# PIC16F1513 register map
Vendor: Microchip
Registers are 8-bit, read-write, reset 0x0 unless marked. A register's access mark holds for its fields unless they carry their own. Addresses are absolute, and some are shared; only a register's first bit layout is shown; [hi:lo] are bit positions; {n}, {i} and the like mark numbered series.

## SFR
0x00 INDF0 reset not defined — (power-on value xxxxxxxx)
0x01 INDF1 reset not defined — (power-on value xxxxxxxx)
0x02 PCL
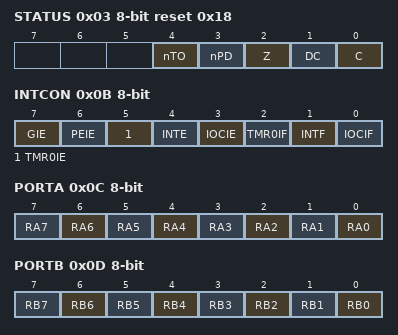
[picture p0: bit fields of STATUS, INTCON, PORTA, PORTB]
0x03 STATUS reset 0x18
  [4] nTO ro, [3] nPD ro, [2] Z, [1] DC, [0] C
0x04 FSR0L
0x05 FSR0H
0x06 FSR1L
0x07 FSR1H
0x08 BSR
  [4:0] BSR
0x09 WREG
  [7:0] WREG0
0x0A PCLATH
  [6:0] PCLATH
0x0B INTCON
  [7] GIE, [6] PEIE, [5] TMR0IE, [4] INTE, [3] IOCIE, [2] TMR0IF, [1] INTF, [0] IOCIF ro
0x0C PORTA reset not defined — (power-on value xxxxxxxx)
  [n] RA{n} (n=0..7)
0x0D PORTB reset not defined — (power-on value xxxxxxxx)
  [n] RB{n} (n=0..7)
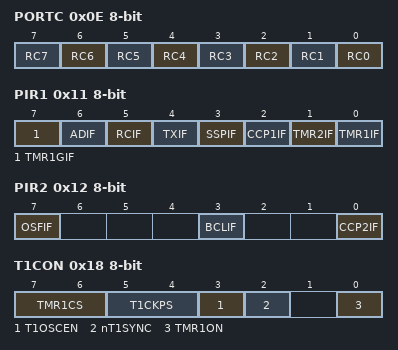
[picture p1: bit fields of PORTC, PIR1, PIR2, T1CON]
0x0E PORTC reset not defined — (power-on value xxxxxxxx)
  [n] RC{n} (n=0..7)
0x10 PORTE ro reset not defined — (power-on value ----x---)
  [3] RE3
0x11 PIR1
  [7] TMR1GIF — Timer1 Gate Interrupt Flag bit
  [6] ADIF — A/D Converter Interrupt Flag bit
  [5] RCIF ro — EUSART Receive Interrupt Flag bit
  [4] TXIF ro — EUSART Transmit Interrupt Flag bit
  [3] SSPIF — Master Synchronous Serial Port (MSSP) Interrupt Flag bit
  [2] CCP1IF — CCP1 Interrupt Flag bit
  [1] TMR2IF — TMR2 to PR2 Match Interrupt Flag bit
  [0] TMR1IF — TMR1 Overflow Interrupt Flag bit
0x12 PIR2
  [7] OSFIF, [3] BCLIF, [0] CCP2IF
0x15 TMR0 reset not defined — (power-on value xxxxxxxx)
0x16 TMR1L reset not defined — (power-on value xxxxxxxx)
0x17 TMR1H reset not defined — (power-on value xxxxxxxx)
0x18 T1CON
  [7:6] TMR1CS, [5:4] T1CKPS, [3] T1OSCEN, [2] nT1SYNC, [0] TMR1ON
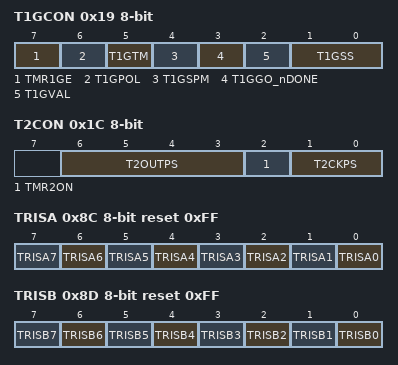
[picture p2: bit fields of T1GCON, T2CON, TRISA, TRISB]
0x19 T1GCON reset not defined — (power-on value 00000x00)
  [7] TMR1GE, [6] T1GPOL, [5] T1GTM, [4] T1GSPM, [3] T1GGO_nDONE, [2] T1GVAL ro, [1:0] T1GSS
0x1A TMR2
0x1B PR2 reset 0xFF
0x1C T2CON
  [6:3] T2OUTPS, [2] TMR2ON, [1:0] T2CKPS
0x8C TRISA reset 0xFF — PORTA Data Direction Control Register
  [n] TRISA{n} (n=0..7)
0x8D TRISB reset 0xFF — PORTB Data Direction Control Register
  [n] TRISB{n} (n=0..7)
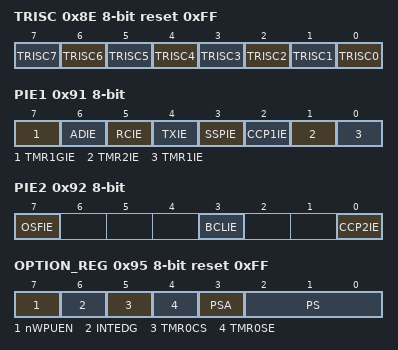
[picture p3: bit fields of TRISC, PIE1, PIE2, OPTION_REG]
0x8E TRISC reset 0xFF — PORTC Data Direction Control Register
  [n] TRISC{n} (n=0..7)
0x90 TRISE access not given reset 0x8
0x91 PIE1 — Peripheral Interrupt Enable Register 1
  [7] TMR1GIE — Timer1 Gate Interrupt Enable bit
  [6] ADIE — A/D Converter Interrupt Enable bit
  [5] RCIE — EUSART Receive Interrupt Enable bit
  [4] TXIE — EUSART Transmit Interrupt Enable bit
  [3] SSPIE — Master Synchronous Serial Port (MSSP) Interrupt Enable bit
  [2] CCP1IE — CCP1 Interrupt Enable bit
  [1] TMR2IE — TMR2 to PR2 Match Interrupt Enable bit
  [0] TMR1IE — TMR1 Overflow Interrupt Enable bit
0x92 PIE2 — Peripheral Interrupt Enable Register 2
  [7] OSFIE — CCP2 Interrupt Enable bit
  [3] BCLIE — MSSP Bus Collision Interrupt Interrupt Enable bit
  [0] CCP2IE — CCP2 Interrupt Enable bit
0x95 OPTION_REG reset 0xFF — Option Register
  [7] nWPUEN — Weak Pull-up Enable bit
  [6] INTEDG — Interrupt Edge Select bit
  [5] TMR0CS — TMR0 Clock Source Select bit
  [4] TMR0SE — TMR0 Source Edge Select bit
  [3] PSA — Prescaler Active bit
  [2:0] PS
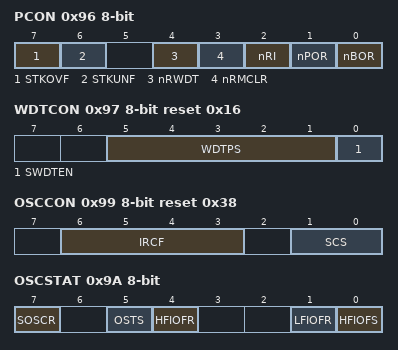
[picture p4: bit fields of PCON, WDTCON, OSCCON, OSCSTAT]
0x96 PCON reset not defined — Power Control Register (power-on value 00-111qq)
  [7] STKOVF — Stack Overflow Flag bit
  [6] STKUNF — Stack Underflow Flag bit
  [4] nRWDT
  [3] nRMCLR — MCLR Reset Flag bit
  [2] nRI — RESET Instruction Flag bit
  [1] nPOR — Power-on Reset Status bit
  [0] nBOR — Brown-out Reset Status bit
0x97 WDTCON reset 0x16 — Watchdog Timer Control Register
  [5:1] WDTPS
  [0] SWDTEN — Software Enable/Disable for Watch Dog Timer bit
0x99 OSCCON reset 0x38 — Oscillator Control Register
  [6:3] IRCF, [1:0] SCS
0x9A OSCSTAT ro reset not defined — Oscillator Status Register (power-on value 0-q0--00)
  [7] SOSCR — Timer1 Oscillator Ready bit
  [5] OSTS — Oscillator Start-up Time-out Status bit
  [4] HFIOFR
  [1] LFIOFR — Low Freqency Internal Oscillator Ready bit
  [0] HFIOFS — Low Freqency Internal Oscillator Ready bit
0x9B ADRES0L reset not defined — A/D Result Register LSB (power-on value xxxxxxxx)
0x9C ADRES0H reset not defined — A/D Result Register MSB (power-on value xxxxxxxx)
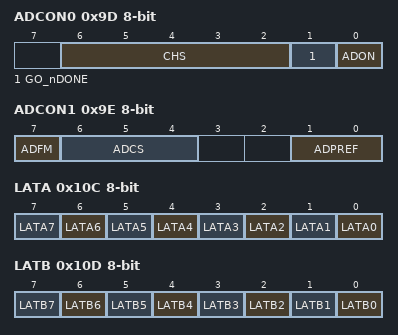
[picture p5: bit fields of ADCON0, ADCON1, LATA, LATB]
0x9D ADCON0 — Analog-to-Digital Control Register 0
  [6:2] CHS
  [1] GO_nDONE — A/D Conversion Status bit
  [0] ADON — A/D Module Enable bit
0x9E ADCON1 — Analog-to-Digital Control Register 1
  [7] ADFM — A/D Result Format Select bit
  [6:4] ADCS
  [1:0] ADPREF
0x10C LATA reset not defined — (power-on value xxxxxxxx)
  [n] LATA{n} (n=0..7)
0x10D LATB reset not defined — (power-on value xxxxxxxx)
  [n] LATB{n} (n=0..7)
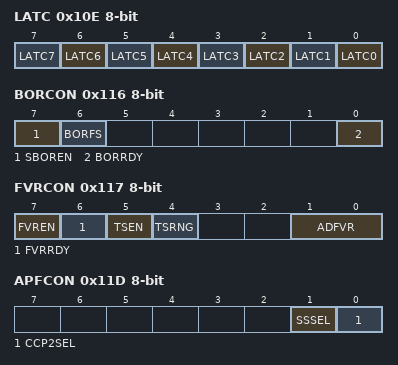
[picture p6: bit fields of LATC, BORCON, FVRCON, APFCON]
0x10E LATC reset not defined — (power-on value xxxxxxxx)
  [n] LATC{n} (n=0..7)
0x116 BORCON reset not defined — Brown-out Reset Control Register (power-on value 10-----q)
  [7] SBOREN — Software Brown Out Reset Enable bit
  [6] BORFS
  [0] BORRDY ro — Brown-out Reset Circuit Ready Status bit
0x117 FVRCON reset not defined — Voltage Reference Control Register 0 (power-on value 0q00--00)
  [7] FVREN — Fixed Voltage Reference Enable
  [6] FVRRDY ro — Fixed Voltage Reference Ready Flag
  [5] TSEN — Temperature Sensor Enable
  [4] TSRNG — Temperature Sensor Range Select
  [1:0] ADFVR — A/D Converter Fixed Voltage Reference Selection
0x11D APFCON — Alternate Pin Function Control Register
  [1] SSSEL — SS Input Pin Selection
  [0] CCP2SEL — CCP2 Input/Output Pin Selection
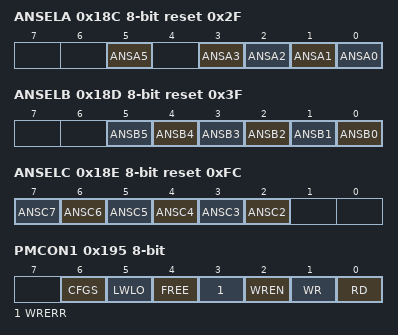
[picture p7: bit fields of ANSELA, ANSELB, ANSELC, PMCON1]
0x18C ANSELA reset 0x2F
  [5] ANSA5, [n] ANSA{n} (n=0..3)
0x18D ANSELB reset 0x3F
  [n] ANSB{n} (n=0..5)
0x18E ANSELC reset 0xFC
  [n] ANSC{n} (n=2..7)
0x191 PMADRL
0x192 PMADRH reset 0x80
  [6:0] PMADRH
0x193 PMDATL reset not defined — (power-on value xxxxxxxx)
0x194 PMDATH reset not defined — (power-on value --xxxxxx)
  [5:0] PMDATH
0x195 PMCON1 reset not defined — (power-on value 1000x000)
  [6] CFGS — FLASH Program / Data EEPROM or Configuration Select bit
  [5] LWLO — Load Write Latches Only bit
  [4] FREE — Program FLASH Erase Enable bit
  [3] WRERR — Sequence Error Flag bit
  [2] WREN — Program/Erase Enable bit
  [1] WR — Write Control bit (can only be set)
  [0] RD — Read Control bit (can only be set)
0x196 PMCON2 wo reset not defined
0x197 VREGCON
  [1] VREGPM
0x199 RCREG ro
0x19A TXREG
0x19B SP1BRGL
  [7:0] SPBRGL
0x19C SP1BRGH
  [7:0] SPBRGH
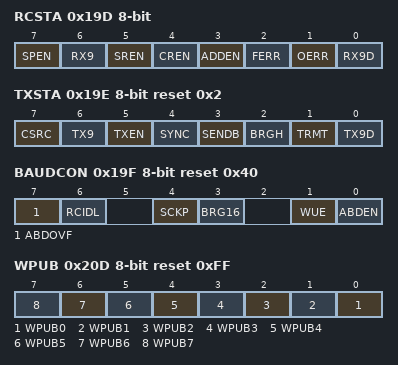
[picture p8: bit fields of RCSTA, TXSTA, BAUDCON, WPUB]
0x19D RCSTA reset not defined — Receive Status and Control Register (power-on value 0000000x)
  [7] SPEN — Serial Port Enable bit
  [6] RX9 — 9-bit Receive Enable bit
  [5] SREN — Single Receive Enable bit
  [4] CREN — Continuous Receive Enable bit
  [3] ADDEN — Address Detect Enable bit
  [2] FERR ro — Framing Error bit
  [1] OERR ro — Overrun Error bit
  [0] RX9D ro — 9th bit of received data (can be parity bit)
0x19E TXSTA reset 0x2 — Transmit Status and Control Register
  [7] CSRC — Clock Source Select bit
  [6] TX9 — 9-bit Transmit Enable bit
  [5] TXEN — Transmit Enable bit
  [4] SYNC — USART Mode Select bit
  [3] SENDB — Send BREAK character bit
  [2] BRGH — High Baud Rate Select bit
  [1] TRMT ro — Transmit Operation Idle Status bit
  [0] TX9D — 9th bit of transmit data; can be used as parity bit
0x19F BAUDCON reset 0x40 — Baud Rate Control Register
  [7] ABDOVF — BRG Rollover Status bit
  [6] RCIDL ro — Receive Operation Idle Status bit
  [4] SCKP — Clock/Transmit Polarity Select bit
  [3] BRG16 — 16-bit Baud Rate Register enable bit
  [1] WUE — Wake-Up Enable bit
  [0] ABDEN — Auto-Baud Detect Enable bit
0x20D WPUB reset 0xFF
  [n] WPUB{n} (n=0..7)
0x210 WPUE reset 0x8
  [3] WPUE3
0x211 SSPBUF reset not defined — (power-on value xxxxxxxx)
0x212 SSPADD
0x213 SSPMSK reset 0xFF
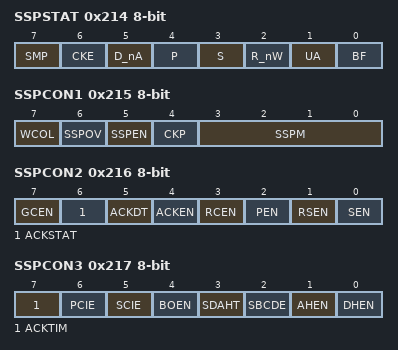
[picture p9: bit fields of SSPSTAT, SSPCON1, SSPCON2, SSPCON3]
0x214 SSPSTAT
  [7] SMP, [6] CKE, [5] D_nA, [4] P, [3] S, [2] R_nW, [1] UA, [0] BF
0x215 SSPCON1
  [7] WCOL, [6] SSPOV, [5] SSPEN, [4] CKP, [3:0] SSPM
0x216 SSPCON2
  [7] GCEN, [6] ACKSTAT, [5] ACKDT, [4] ACKEN, [3] RCEN, [2] PEN, [1] RSEN, [0] SEN
0x217 SSPCON3
  [7] ACKTIM, [6] PCIE, [5] SCIE, [4] BOEN, [3] SDAHT, [2] SBCDE, [1] AHEN, [0] DHEN
0x291 CCPR1L reset not defined — (power-on value xxxxxxxx)
0x292 CCPR1H reset not defined — (power-on value xxxxxxxx)
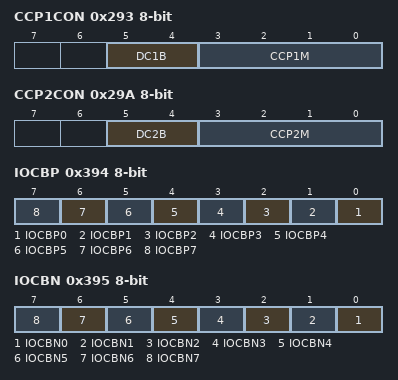
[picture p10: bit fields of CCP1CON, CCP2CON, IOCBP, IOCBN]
0x293 CCP1CON
  [5:4] DC1B, [3:0] CCP1M
0x298 CCPR2L reset not defined — (power-on value xxxxxxxx)
0x299 CCPR2H reset not defined — (power-on value xxxxxxxx)
0x29A CCP2CON
  [5:4] DC2B, [3:0] CCP2M
0x394 IOCBP — Interrupt-On-Change Positive Edge Register
  [n] IOCBP{n} (n=0..7)
0x395 IOCBN — Interrupt-On-Change Negative Edge Register
  [n] IOCBN{n} (n=0..7)
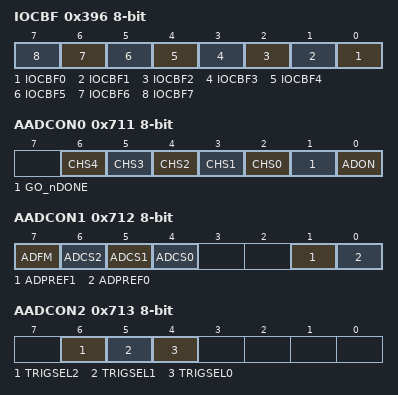
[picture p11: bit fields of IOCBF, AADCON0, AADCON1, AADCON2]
0x396 IOCBF — Interrupt-On-Change Flag Register
  [n] IOCBF{n} (n=0..7)
0x711 AADCON0
  [n+2] CHS{n} (n=0..4), [1] GO_nDONE, [0] ADON
0x712 AADCON1
  [7] ADFM, [6] ADCS2, [5] ADCS1, [4] ADCS0, [1] ADPREF1, [0] ADPREF0
0x713 AADCON2
  [6] TRIGSEL2, [5] TRIGSEL1, [4] TRIGSEL0
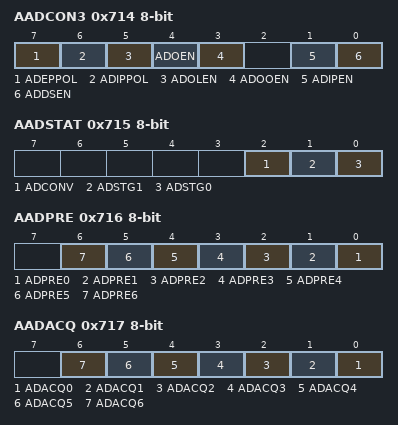
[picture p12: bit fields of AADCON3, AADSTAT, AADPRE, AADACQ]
0x714 AADCON3
  [7] ADEPPOL, [6] ADIPPOL, [5] ADOLEN, [4] ADOEN, [3] ADOOEN, [1] ADIPEN, [0] ADDSEN
0x715 AADSTAT
  [2] ADCONV, [1] ADSTG1, [0] ADSTG0
0x716 AADPRE
  [n] ADPRE{n} (n=0..6)
0x717 AADACQ
  [n] ADACQ{n} (n=0..6)
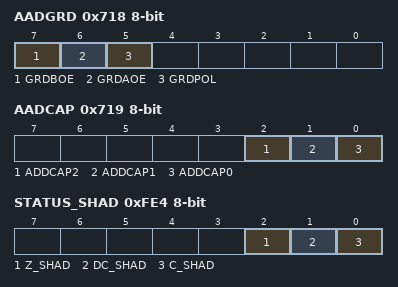
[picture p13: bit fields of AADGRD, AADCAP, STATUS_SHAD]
0x718 AADGRD
  [7] GRDBOE, [6] GRDAOE, [5] GRDPOL
0x719 AADCAP
  [2] ADDCAP2, [1] ADDCAP1, [0] ADDCAP0
0x71A AADRES0L reset not defined — (power-on value xxxxxxxx)
  [7:0] ADRES0L
0x71B AADRES0H reset not defined — (power-on value xxxxxxxx)
  [7:0] ADRES0H
0x71C AADRES1L reset not defined — (power-on value xxxxxxxx)
  [7:0] ADRES1L
0x71D AADRES1H reset not defined — (power-on value xxxxxxxx)
  [7:0] ADRES1H
0xFE4 STATUS_SHAD reset not defined — (power-on value -----xxx)
  [2] Z_SHAD, [1] DC_SHAD, [0] C_SHAD
0xFE5 WREG_SHAD reset not defined — (power-on value xxxxxxxx)
0xFE6 BSR_SHAD reset not defined — (power-on value ---xxxxx)
  [4:0] BSR_SHAD
0xFE7 PCLATH_SHAD reset not defined — (power-on value -xxxxxxx)
  [6:0] PCLATH_SHAD
0xFE8 FSR0L_SHAD reset not defined — (power-on value xxxxxxxx)
0xFE9 FSR0H_SHAD reset not defined — (power-on value xxxxxxxx)
0xFEA FSR1L_SHAD reset not defined — (power-on value xxxxxxxx)
0xFEB FSR1H_SHAD reset not defined — (power-on value xxxxxxxx)
0xFED STKPTR reset 0x1F — Current Stack pointer
  [4:0] STKPTR
0xFEE TOSL reset not defined — Top of Stack Low byte (power-on value xxxxxxxx)
0xFEF TOSH reset not defined — Top of Stack High byte (power-on value -xxxxxxx)
  [6:0] TOSH
